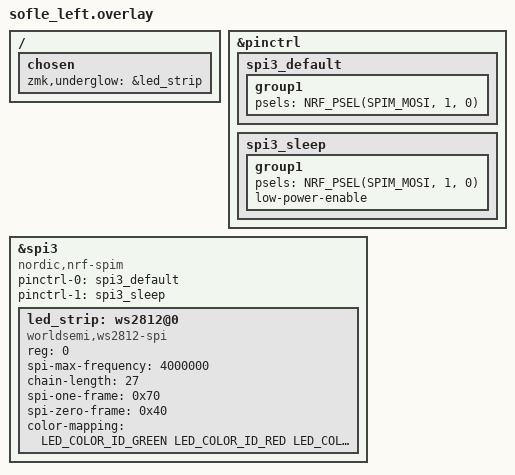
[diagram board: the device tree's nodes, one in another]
/*
 * RGB underglow (WS2812/SK6812) on the left half.
 * Data line is wired to pro_micro pin 6 (D6), which is P1.00 on nice_nano.
 * Driven over spi3 (unused by this shield) with MOSI remapped to that pin.
 */

#include <dt-bindings/led/led.h>

&pinctrl {
    spi3_default: spi3_default {
        group1 {
            psels = <NRF_PSEL(SPIM_MOSI, 1, 0)>;
        };
    };

    spi3_sleep: spi3_sleep {
        group1 {
            psels = <NRF_PSEL(SPIM_MOSI, 1, 0)>;
            low-power-enable;
        };
    };
};

&spi3 {
    compatible = "nordic,nrf-spim";
    status = "okay";

    pinctrl-0 = <&spi3_default>;
    pinctrl-1 = <&spi3_sleep>;
    pinctrl-names = "default", "sleep";

    led_strip: ws2812@0 {
        compatible = "worldsemi,ws2812-spi";

        /* SPI */
        reg = <0>; /* ignored, but necessary for SPI bindings */
        spi-max-frequency = <4000000>;

        /* WS2812 */
        chain-length = <27>;
        spi-one-frame = <0x70>;
        spi-zero-frame = <0x40>;

        color-mapping = <LED_COLOR_ID_GREEN LED_COLOR_ID_RED LED_COLOR_ID_BLUE>;
    };
};

/ {
    chosen {
        zmk,underglow = &led_strip;
    };
};
